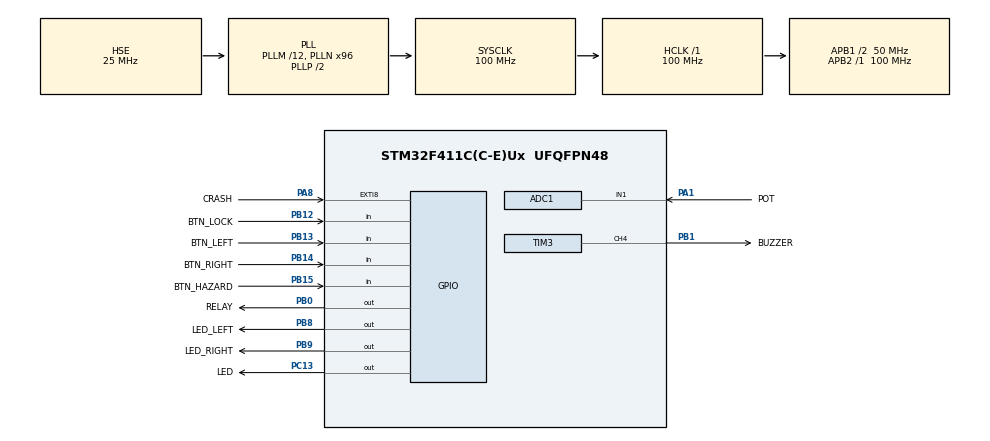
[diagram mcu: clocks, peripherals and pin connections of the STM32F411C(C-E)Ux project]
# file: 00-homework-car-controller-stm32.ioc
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ADC1.Channel-0\#ChannelRegularConversion=ADC_CHANNEL_1
ADC1.NbrOfConversionFlag=1
ADC1.Rank-0\#ChannelRegularConversion=1
ADC1.SamplingTime-0\#ChannelRegularConversion=ADC_SAMPLETIME_84CYCLES
ADC1.master=1
Mcu.Family=STM32F4
Mcu.Name=STM32F411C(C-E)Ux
Mcu.Package=UFQFPN48
NVIC.EXTI9_5_IRQn=true\:0\:0\:false\:false\:true\:true\:true\:true
NVIC.PriorityGroup=NVIC_PRIORITYGROUP_4
PA1.GPIO_Label=POT
PA1.Signal=ADCx_IN1
PA13.Mode=Serial_Wire
PA13.Signal=SYS_JTMS-SWDIO
PA14.Mode=Serial_Wire
PA14.Signal=SYS_JTCK-SWCLK
PA8.GPIO_Label=CRASH
PA8.GPIO_ModeDefaultEXTI=GPIO_MODE_IT_FALLING
PA8.GPIO_PuPd=GPIO_PULLUP
PA8.Signal=GPXTI8
PB0.GPIO_Label=RELAY
PB0.Signal=GPIO_Output
PB1.GPIO_Label=BUZZER
PB1.Signal=S_TIM3_CH4
PB12.GPIO_Label=BTN_LOCK
PB12.GPIO_PuPd=GPIO_PULLUP
PB12.Signal=GPIO_Input
PB13.GPIO_Label=BTN_LEFT
PB13.GPIO_PuPd=GPIO_PULLUP
PB13.Signal=GPIO_Input
PB14.GPIO_Label=BTN_RIGHT
PB14.GPIO_PuPd=GPIO_PULLUP
PB14.Signal=GPIO_Input
PB15.GPIO_Label=BTN_HAZARD
PB15.GPIO_PuPd=GPIO_PULLUP
PB15.Signal=GPIO_Input
PB8.GPIO_Label=LED_LEFT
PB8.Signal=GPIO_Output
PB9.GPIO_Label=LED_RIGHT
PB9.Signal=GPIO_Output
PC13-ANTI_TAMP.GPIO_Label=LED
PC13-ANTI_TAMP.Signal=GPIO_Output
PH0\ -\ OSC_IN.Mode=HSE-External-Oscillator
PH0\ -\ OSC_IN.Signal=RCC_OSC_IN
PH1\ -\ OSC_OUT.Mode=HSE-External-Oscillator
PH1\ -\ OSC_OUT.Signal=RCC_OSC_OUT
ProjectManager.HeapSize=0x200
ProjectManager.StackSize=0x400
ProjectManager.TargetToolchain=STM32CubeIDE
RCC.48MHZClocksFreq_Value=50000000
RCC.AHBFreq_Value=100000000
RCC.APB1CLKDivider=RCC_HCLK_DIV2
RCC.APB1Freq_Value=50000000
RCC.APB1TimFreq_Value=100000000
RCC.APB2Freq_Value=100000000
RCC.APB2TimFreq_Value=100000000
RCC.CortexFreq_Value=100000000
RCC.HCLKFreq_Value=100000000
RCC.HSE_VALUE=25000000
RCC.HSI_VALUE=16000000
RCC.LSE_VALUE=32768
RCC.PLLM=12
RCC.PLLN=96
RCC.PLLSourceVirtual=RCC_PLLSOURCE_HSE
RCC.SYSCLKFreq_VALUE=100000000
RCC.SYSCLKSource=RCC_SYSCLKSOURCE_PLLCLK
RCC.VCOOutputFreq_Value=200000000
SH.ADCx_IN1.0=ADC1_IN1,IN1
SH.S_TIM3_CH4.0=TIM3_CH4,PWM Generation4 CH4
TIM3.AutoReloadPreload=TIM_AUTORELOAD_PRELOAD_ENABLE
TIM3.Channel-PWM\ Generation4\ CH4=TIM_CHANNEL_4
TIM3.Period=1249
TIM3.Prescaler=99
board=custom

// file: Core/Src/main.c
/* USER CODE BEGIN Header */
/**
  ******************************************************************************
  * @file           : main.c
  * @brief          : Main program body
  ******************************************************************************
  * @attention
  *
  * Copyright (c) 2026 STMicroelectronics.
  * All rights reserved.
  *
  * This software is licensed under terms that can be found in the LICENSE file
  * in the root directory of this software component.
  * If no LICENSE file comes with this software, it is provided AS-IS.
  *
  ******************************************************************************
  */
/* USER CODE END Header */
#include "main.h"

/* USER CODE BEGIN Includes */
#include "app.h"
/* USER CODE END Includes */

ADC_HandleTypeDef hadc1;

TIM_HandleTypeDef htim3;

void SystemClock_Config(void);
static void MX_GPIO_Init(void);
static void MX_TIM3_Init(void);
static void MX_ADC1_Init(void);

int main(void)
{

  /* MCU Configuration--------------------------------------------------------*/

  /* Reset of all peripherals, Initializes the Flash interface and the Systick. */
  HAL_Init();

  /* Configure the system clock */
  SystemClock_Config();

  /* Initialize all configured peripherals */
  MX_GPIO_Init();
  MX_TIM3_Init();
  MX_ADC1_Init();
  /* USER CODE BEGIN 2 */
  app_init(); /* our code starts here: the drivers, the buttons */
  /* USER CODE END 2 */

  /* Infinite loop */
  while (1)
  {

    /* USER CODE BEGIN 3 */
	  app_loop(); /* one pass of the superloop: app.c, never blocks */
  }
  /* USER CODE END 3 */
}

void SystemClock_Config(void)
{
  RCC_OscInitTypeDef RCC_OscInitStruct = {0};
  RCC_ClkInitTypeDef RCC_ClkInitStruct = {0};

  /** Configure the main internal regulator output voltage
  */
  __HAL_RCC_PWR_CLK_ENABLE();
  __HAL_PWR_VOLTAGESCALING_CONFIG(PWR_REGULATOR_VOLTAGE_SCALE1);

  /** Initializes the RCC Oscillators according to the specified parameters
  * in the RCC_OscInitTypeDef structure.
  */
  RCC_OscInitStruct.OscillatorType = RCC_OSCILLATORTYPE_HSE;
  RCC_OscInitStruct.HSEState = RCC_HSE_ON;
  RCC_OscInitStruct.PLL.PLLState = RCC_PLL_ON;
  RCC_OscInitStruct.PLL.PLLSource = RCC_PLLSOURCE_HSE;
  RCC_OscInitStruct.PLL.PLLM = 12;
  RCC_OscInitStruct.PLL.PLLN = 96;
  RCC_OscInitStruct.PLL.PLLP = RCC_PLLP_DIV2;
  RCC_OscInitStruct.PLL.PLLQ = 4;
  if (HAL_RCC_OscConfig(&RCC_OscInitStruct) != HAL_OK)
  {
    Error_Handler();
  }

  /** Initializes the CPU, AHB and APB buses clocks
  */
  RCC_ClkInitStruct.ClockType = RCC_CLOCKTYPE_HCLK|RCC_CLOCKTYPE_SYSCLK
                              |RCC_CLOCKTYPE_PCLK1|RCC_CLOCKTYPE_PCLK2;
  RCC_ClkInitStruct.SYSCLKSource = RCC_SYSCLKSOURCE_PLLCLK;
  RCC_ClkInitStruct.AHBCLKDivider = RCC_SYSCLK_DIV1;
  RCC_ClkInitStruct.APB1CLKDivider = RCC_HCLK_DIV2;
  RCC_ClkInitStruct.APB2CLKDivider = RCC_HCLK_DIV1;

  if (HAL_RCC_ClockConfig(&RCC_ClkInitStruct, FLASH_LATENCY_3) != HAL_OK)
  {
    Error_Handler();
  }
}

static void MX_ADC1_Init(void)
{

  ADC_ChannelConfTypeDef sConfig = {0};

  /** Configure the global features of the ADC (Clock, Resolution, Data Alignment and number of conversion)
  */
  hadc1.Instance = ADC1;
  hadc1.Init.ClockPrescaler = ADC_CLOCK_SYNC_PCLK_DIV4;
  hadc1.Init.Resolution = ADC_RESOLUTION_12B;
  hadc1.Init.ScanConvMode = DISABLE;
  hadc1.Init.ContinuousConvMode = DISABLE;
  hadc1.Init.DiscontinuousConvMode = DISABLE;
  hadc1.Init.ExternalTrigConvEdge = ADC_EXTERNALTRIGCONVEDGE_NONE;
  hadc1.Init.ExternalTrigConv = ADC_SOFTWARE_START;
  hadc1.Init.DataAlign = ADC_DATAALIGN_RIGHT;
  hadc1.Init.NbrOfConversion = 1;
  hadc1.Init.DMAContinuousRequests = DISABLE;
  hadc1.Init.EOCSelection = ADC_EOC_SINGLE_CONV;
  if (HAL_ADC_Init(&hadc1) != HAL_OK)
  {
    Error_Handler();
  }

  /** Configure for the selected ADC regular channel its corresponding rank in the sequencer and its sample time.
  */
  sConfig.Channel = ADC_CHANNEL_1;
  sConfig.Rank = 1;
  sConfig.SamplingTime = ADC_SAMPLETIME_84CYCLES;
  if (HAL_ADC_ConfigChannel(&hadc1, &sConfig) != HAL_OK)
  {
    Error_Handler();
  }

}

static void MX_TIM3_Init(void)
{

  TIM_MasterConfigTypeDef sMasterConfig = {0};
  TIM_OC_InitTypeDef sConfigOC = {0};

  htim3.Instance = TIM3;
  htim3.Init.Prescaler = 99;
  htim3.Init.CounterMode = TIM_COUNTERMODE_UP;
  htim3.Init.Period = 1249;
  htim3.Init.ClockDivision = TIM_CLOCKDIVISION_DIV1;
  htim3.Init.AutoReloadPreload = TIM_AUTORELOAD_PRELOAD_ENABLE;
  if (HAL_TIM_PWM_Init(&htim3) != HAL_OK)
  {
    Error_Handler();
  }
  sMasterConfig.MasterOutputTrigger = TIM_TRGO_RESET;
  sMasterConfig.MasterSlaveMode = TIM_MASTERSLAVEMODE_DISABLE;
  if (HAL_TIMEx_MasterConfigSynchronization(&htim3, &sMasterConfig) != HAL_OK)
  {
    Error_Handler();
  }
  sConfigOC.OCMode = TIM_OCMODE_PWM1;
  sConfigOC.Pulse = 0;
  sConfigOC.OCPolarity = TIM_OCPOLARITY_HIGH;
  sConfigOC.OCFastMode = TIM_OCFAST_DISABLE;
  if (HAL_TIM_PWM_ConfigChannel(&htim3, &sConfigOC, TIM_CHANNEL_4) != HAL_OK)
  {
    Error_Handler();
  }
  HAL_TIM_MspPostInit(&htim3);

}

static void MX_GPIO_Init(void)
{
  GPIO_InitTypeDef GPIO_InitStruct = {0};

  /* GPIO Ports Clock Enable */
  __HAL_RCC_GPIOC_CLK_ENABLE();
  __HAL_RCC_GPIOH_CLK_ENABLE();
  __HAL_RCC_GPIOA_CLK_ENABLE();
  __HAL_RCC_GPIOB_CLK_ENABLE();

  /*Configure GPIO pin Output Level */
  HAL_GPIO_WritePin(LED_GPIO_Port, LED_Pin, GPIO_PIN_RESET);

  /*Configure GPIO pin Output Level */
  HAL_GPIO_WritePin(GPIOB, RELAY_Pin|LED_LEFT_Pin|LED_RIGHT_Pin, GPIO_PIN_RESET);

  /*Configure GPIO pin : LED_Pin */
  GPIO_InitStruct.Pin = LED_Pin;
  GPIO_InitStruct.Mode = GPIO_MODE_OUTPUT_PP;
  GPIO_InitStruct.Pull = GPIO_NOPULL;
  GPIO_InitStruct.Speed = GPIO_SPEED_FREQ_LOW;
  HAL_GPIO_Init(LED_GPIO_Port, &GPIO_InitStruct);

  /*Configure GPIO pins : RELAY_Pin LED_LEFT_Pin LED_RIGHT_Pin */
  GPIO_InitStruct.Pin = RELAY_Pin|LED_LEFT_Pin|LED_RIGHT_Pin;
  GPIO_InitStruct.Mode = GPIO_MODE_OUTPUT_PP;
  GPIO_InitStruct.Pull = GPIO_NOPULL;
  GPIO_InitStruct.Speed = GPIO_SPEED_FREQ_LOW;
  HAL_GPIO_Init(GPIOB, &GPIO_InitStruct);

  /*Configure GPIO pins : BTN_LOCK_Pin BTN_LEFT_Pin BTN_RIGHT_Pin BTN_HAZARD_Pin */
  GPIO_InitStruct.Pin = BTN_LOCK_Pin|BTN_LEFT_Pin|BTN_RIGHT_Pin|BTN_HAZARD_Pin;
  GPIO_InitStruct.Mode = GPIO_MODE_INPUT;
  GPIO_InitStruct.Pull = GPIO_PULLUP;
  HAL_GPIO_Init(GPIOB, &GPIO_InitStruct);

  /*Configure GPIO pin : CRASH_Pin */
  GPIO_InitStruct.Pin = CRASH_Pin;
  GPIO_InitStruct.Mode = GPIO_MODE_IT_FALLING;
  GPIO_InitStruct.Pull = GPIO_PULLUP;
  HAL_GPIO_Init(CRASH_GPIO_Port, &GPIO_InitStruct);

  /* EXTI interrupt init*/
  HAL_NVIC_SetPriority(EXTI9_5_IRQn, 0, 0);
  HAL_NVIC_EnableIRQ(EXTI9_5_IRQn);

}

void Error_Handler(void)
{
  __disable_irq();
  while (1)
  {
  }
}
